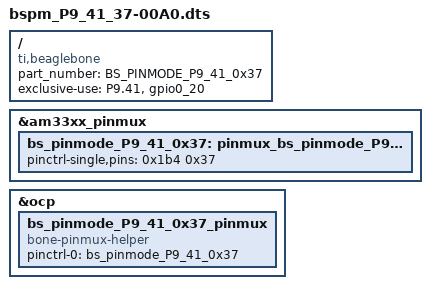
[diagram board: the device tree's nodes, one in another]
/*
 * This is a template-generated file from BoneScript
 */

/dts-v1/;
/plugin/;

/{
    compatible = "ti,beaglebone", "ti,beaglebone-black";
    part_number = "BS_PINMODE_P9_41_0x37";

    exclusive-use =
        "P9.41",
        "gpio0_20";

    fragment@0 {
        target = <&am33xx_pinmux>;
        __overlay__ {
            bs_pinmode_P9_41_0x37: pinmux_bs_pinmode_P9_41_0x37 {
                pinctrl-single,pins = <0x1b4 0x37>;
            };
        };
    };

    fragment@1 {
        target = <&ocp>;
        __overlay__ {
            bs_pinmode_P9_41_0x37_pinmux {
                compatible = "bone-pinmux-helper";
                status = "okay";
                pinctrl-names = "default";
                pinctrl-0 = <&bs_pinmode_P9_41_0x37>;
            };
        };
    };
};
